# PIC32CX1012BZ25048 register map
Vendor: Microchip Technology; Series: BZ25; File version: 0
CPU: CM4 r0p1, little endian, MPU, FPU, 3 interrupt priority bits
Registers are 32-bit, read-write, reset 0x0 unless marked. A register's access mark holds for its fields unless they carry their own. Offsets are from the block's base; [hi:lo] are bit positions; {n}, {i} and the like mark numbered series; 'fields as' and 'values as' point back to an identical list.

## AES — Advanced Encryption Standard
Base 0x42000400; register names take the prefix AES_
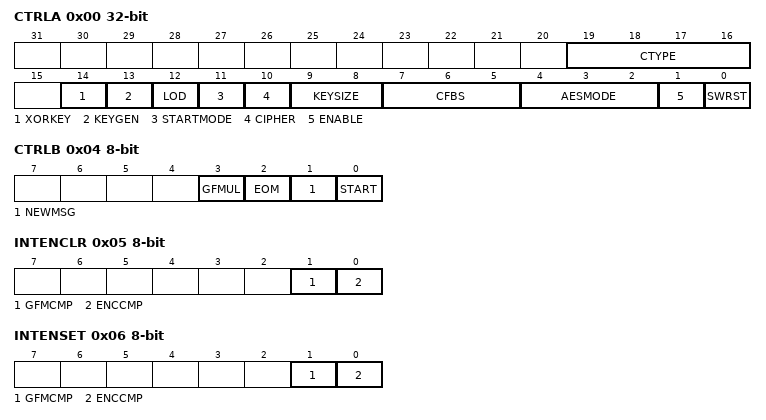
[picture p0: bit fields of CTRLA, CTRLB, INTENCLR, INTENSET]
0x00 CTRLA — Control A
  [19:16] CTYPE — Counter Measure Type
  [14] XORKEY — XOR Key Operation
    0=NONE (No effect); 1=XOR (The user keyword gets XORed with the previous keyword register content.)
  [13] KEYGEN — Last Key Generation
    0=NONE (No effect); 1=LAST (Start Computation of the last NK words of the expanded key)
  [12] LOD — Last Output Data Mode
    0=NONE (No effect); 1=LAST (Start encryption in Last Output Data mode)
  [11] STARTMODE — Start Mode Select
    0=MANUAL (Start Encryption / Decryption in Manual mode); 1=AUTO (Start Encryption / Decryption in Auto mode)
  [10] CIPHER — Cipher Mode
    0=DEC (Decryption); 1=ENC (Encryption)
  [9:8] KEYSIZE — Encryption Key Size
    0=128BIT (128-bit Key for Encryption / Decryption); 1=192BIT (192-bit Key for Encryption / Decryption); 2=256BIT (256-bit Key for Encryption / Decryption)
  [7:5] CFBS — Cipher Feedback Block Size
    0=128BIT (128-bit Input data block for Encryption/Decryption in Cipher Feedback mode); 1=64BIT (64-bit Input data block for Encryption/Decryption in Cipher Feedback mode); 2=32BIT (32-bit Input data block for Encryption/Decryption in Cipher Feedback mode); 3=16BIT (16-bit Input data block for Encryption/Decryption in Cipher Feedback mode); 4=8BIT (8-bit Input data block for Encryption/Decryption in Cipher Feedback mode)
  [4:2] AESMODE — AES Modes of operation
    0=ECB (Electronic code book mode); 1=CBC (Cipher block chaining mode); 2=OFB (Output feedback mode); 3=CFB (Cipher feedback mode); 4=COUNTER (Counter mode); 5=CCM (CCM mode); 6=GCM (Galois counter mode)
  [1] ENABLE
  [0] SWRST — Software Reset
0x04 CTRLB 8-bit — Control B
  [3] GFMUL — GF Multiplication
  [2] EOM — End of message
  [1] NEWMSG — New message
  [0] START — Start Encryption/Decryption
0x05 INTENCLR 8-bit — Interrupt Enable Clear
  [1] GFMCMP — GF Multiplication Complete Interrupt Enable
  [0] ENCCMP — Encryption Complete Interrupt Enable
0x06 INTENSET 8-bit — Interrupt Enable Set
  fields as INTENCLR
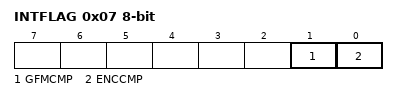
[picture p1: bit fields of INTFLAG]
0x07 INTFLAG 8-bit — Interrupt Flag Status
  [1] GFMCMP — GF Multiplication Complete
  [0] ENCCMP — Encryption Complete
0x08 DATABUFPTR 8-bit — Data buffer pointer
  [1:0] INDATAPTR — Input Data Pointer
0x09 DBGCTRL 8-bit — Debug control
  [0] DBGRUN — Debug Run
{0xC+4i} KEYWORD[{i}] (i=0..7) wo — Keyword n
0x38 INDATA
{0x3C+4i} INTVECTV[{i}] (i=0..3) wo — Initialisation Vector n
{0x5C+4i} HASHKEY[{i}] (i=0..3) — Hash key n
{0x6C+4i} GHASH[{i}] (i=0..3) — Galois Hash n
0x80 CIPLEN — Cipher Length
0x84 RANDSEED — Random Seed

## BLE
Base 0x41012000; register names take the prefix BLE_
0x4B8 DPLL_RG1 16-bit
  [15:0] DPLL_RG1BITS
0x4BA DPLL_RG2 16-bit
  [15:0] DPLL_RG2BITS

## BTZBSYS — BT ZB Subsystem
Base 0x41014000; register names take the prefix BTZBSYS_
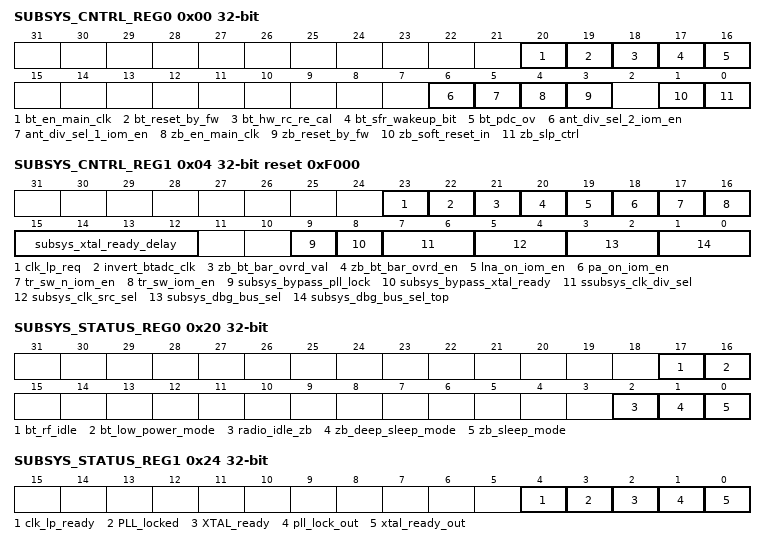
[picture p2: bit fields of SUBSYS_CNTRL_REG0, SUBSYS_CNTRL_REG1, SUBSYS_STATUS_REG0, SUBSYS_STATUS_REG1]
0x00 SUBSYS_CNTRL_REG0
  [20] bt_en_main_clk, [19] bt_reset_by_fw, [18] bt_hw_rc_re_cal, [17] bt_sfr_wakeup_bit, [16] bt_pdc_ov, [6] ant_div_sel_2_iom_en, [5] ant_div_sel_1_iom_en, [4] zb_en_main_clk, [3] zb_reset_by_fw, [1] zb_soft_reset_in, [0] zb_slp_ctrl
0x04 SUBSYS_CNTRL_REG1 reset 0xF000
  [23] clk_lp_req
  [22] invert_btadc_clk
  [21] zb_bt_bar_ovrd_val
  [20] zb_bt_bar_ovrd_en
  [19] lna_on_iom_en
  [18] pa_on_iom_en
  [17] tr_sw_n_iom_en
  [16] tr_sw_iom_en
  [15:12] subsys_xtal_ready_delay
  [9] subsys_bypass_pll_lock
  [8] subsys_bypass_xtal_ready
  [7:6] ssubsys_clk_div_sel — subsys_clk_div_sel
  [5:4] subsys_clk_src_sel
  [3:2] subsys_dbg_bus_sel
  [1:0] subsys_dbg_bus_sel_top
0x20 SUBSYS_STATUS_REG0
  [17] bt_rf_idle, [16] bt_low_power_mode, [2] radio_idle_zb, [1] zb_deep_sleep_mode, [0] zb_sleep_mode
0x24 SUBSYS_STATUS_REG1
  [4] clk_lp_ready, [3] PLL_locked, [2] XTAL_ready, [1] pll_lock_out, [0] xtal_ready_out

## Notices in the file
Copyright (c) 2017 Microchip Technology Inc.
SPDX-License-Identifier: Apache-2.0
Licensed under the Apache License, Version 2.0 (the "License");
you may not use this file except in compliance with the License.
You may obtain a copy of the License at
http://www.apache.org/licenses/LICENSE-2.0
Unless required by applicable law or agreed to in writing, software
distributed under the License is distributed on an "AS IS" BASIS,
WITHOUT WARRANTIES OR CONDITIONS OF ANY KIND, either express or implied.
See the License for the specific language governing permissions and
limitations under the License.
